# STM32L0x2 register map
File version: 1.7
CPU: CM0+ r0p0, little endian, MPU, no FPU, 2 interrupt priority bits
Registers are 32-bit, read-write, reset 0x0 unless marked. A register's access mark holds for its fields unless they carry their own. Offsets are from the block's base; [hi:lo] are bit positions; {n}, {i} and the like mark numbered series; 'fields as' and 'values as' point back to an identical list.

## SYSCFG — System configuration controller and Comparator
Base 0x40010000
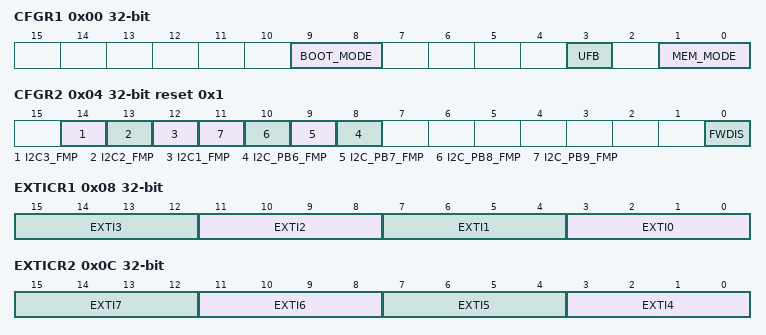
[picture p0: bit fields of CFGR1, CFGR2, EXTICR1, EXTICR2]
0x00 CFGR1 access not given — SYSCFG configuration register 1
  [9:8] BOOT_MODE ro — Boot mode selected by the boot pins status bits
    0=Main Flash memory boot mode; 1=System Flash memory boot mode; 3=SRAM (Embedded SRAM boot mode)
  [3] UFB — User bank swapping
    0=Bank1 (Flash Program memory Bank 1 is mapped at 0x0800 0000 (and aliased at 0x0000 0000 if MEM_MODE=00) and Data EEPROM Bank 1 at 0x0808 0000 (aliased at 0x0008 0000 if MEM_MODE=00)); 1=Bank2 (Flash Program memory Bank 2 is mapped at 0x0800 0000 (and aliased at 0x0000 0000 if MEM_MODE=00) and Data EEPROM Bank 2 at 0x0808 0000 (and aliased at 0x0008 0000 if MEM_MODE=00))
  [1:0] MEM_MODE rw — Memory mapping selection bits
    0=Main Flash memory mapped at 0x0000_0000; 1=System Flash memory mapped at 0x0000_0000; 3=SRAM (Embedded SRAM mapped at 0x0000_0000)
0x04 CFGR2 reset 0x1 — SYSCFG configuration register 2
  [14] I2C3_FMP — I2C3 Fm+ drive capability enable bit
    0=Standard (FM+ mode is controlled by I2C_Pxx_FMP bits only); 1=FMP (FM+ mode is enabled on all I2C3 pins selected through selection bits in GPIOx_AFR registers)
  [13] I2C2_FMP — I2C2 Fm+ drive capability enable bit
    0=Standard (FM+ mode is controlled by I2C_Pxx_FMP bits only); 1=FMP (FM+ mode is enabled on all I2C2 pins selected through selection bits in GPIOx_AFR registers)
  [12] I2C1_FMP — I2C1 Fm+ drive capability enable bit
    0=Standard (FM+ mode is controlled by I2C_Pxx_FMP bits only); 1=FMP (FM+ mode is enabled on all I2C1 pins selected through selection bits in GPIOx_AFR registers)
  [n+2] I2C_PB{n}_FMP (n=6..9) — Fm+ drive capability on PB{n} enable bit
    0=Standard (PB{n} pin operate in standard mode); 1=FMP (I2C FM+ mode enabled on PB{n} and the Speed control is bypassed)
  [0] FWDIS — Firewall disable bit
    0=Enabled (Firewall access enabled); 1=Disabled (Firewall access disabled)
0x08 EXTICR1 — external interrupt configuration register 1
  [all] fields
    0=PA (Select PAx as the source input for the EXTIx external interrupt); 1=PB (Select PBx as the source input for the EXTIx external interrupt); 2=PC (Select PCx as the source input for the EXTIx external interrupt); 3=PD (Select PDx as the source input for the EXTIx external interrupt); 4=PE (Select PEx as the source input for the EXTIx external interrupt); 5=PH (Select PHx as the source input for the EXTIx external interrupt)
  [4n+3:4n] EXTI{n} (n=0..3) — EXTI x configuration (x = 0 to 3)
0x0C EXTICR2 — external interrupt configuration register 2
  [all] fields
    0=PA (Select PAx as the source input for the EXTIx external interrupt); 1=PB (Select PBx as the source input for the EXTIx external interrupt); 2=PC (Select PCx as the source input for the EXTIx external interrupt); 3=PD (Select PDx as the source input for the EXTIx external interrupt); 4=PE (Select PEx as the source input for the EXTIx external interrupt)
  [4n-13:4n-16] EXTI{n} (n=4..7) — EXTI x configuration (x = 4 to 7)
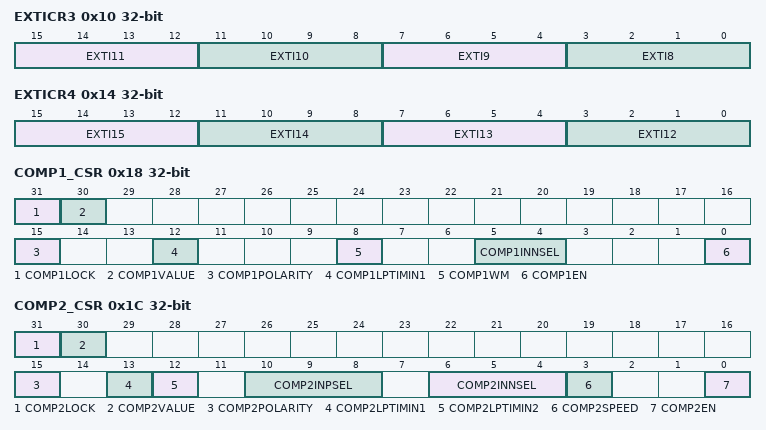
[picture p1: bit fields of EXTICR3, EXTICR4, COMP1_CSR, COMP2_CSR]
0x10 EXTICR3 — external interrupt configuration register 3
  [all] fields
    values as the fields of EXTICR1
  [15:12] EXTI11 — EXTI x configuration (x = 8 to 11)
  [11:8] EXTI10
  [7:4] EXTI9 — EXTI x configuration (x = 8 to 11)
  [3:0] EXTI8 — EXTI x configuration (x = 8 to 11)
0x14 EXTICR4 — external interrupt configuration register 4
  [all] fields
    values as the fields of EXTICR2
  [15:12] EXTI15 — EXTI x configuration (x = 12 to 15)
  [11:8] EXTI14
  [7:4] EXTI13
  [3:0] EXTI12
0x18 COMP1_CSR access per field — Comparator 1 control and status register
  [31] COMP1LOCK ro — COMP1_CSR register lock bit
    0=ReadWrite (COMP1_CSR[31:0] for comparator 1 are read/write); 1=ReadOnly (COMP1_CSR[31:0] for comparator 1 are read-only)
  [30] COMP1VALUE ro — Comparator 1 output status bit
    0=NotEqual (Comparator values are not equal); 1=Equal (Comparator values are equal)
  [15] COMP1POLARITY rw — Comparator 1 polarity selection bit
    0=NotInverted (Comparator 1 output value not inverted); 1=Inverted (Comparator 1 output value inverted)
  [12] COMP1LPTIMIN1 rw — Comparator 1 LPTIM input propagation bit
    0=Gated (Comparator 1 output gated); 1=NotGated (Comparator 1 output sent to LPTIM input 1)
  [8] COMP1WM rw — Comparator 1 window mode selection bit
    0=PA1 (Plus input of comparator 1 connected to PA1); 1=Comp2Plus (Plus input of comparator 1 shorted with Plus input of comparator 2 (see COMP1_CSR))
  [5:4] COMP1INNSEL rw — Comparator 1 Input Minus connection configuration bit
    0=VREFINT; 1=PA0; 2=PA4; 3=PA5
  [0] COMP1EN rw — Comparator 1 enable bit
    0=Disabled (Comparator 1 switched OFF); 1=Enabled (Comparator 1 switched ON)
0x1C COMP2_CSR access per field — Comparator 2 control and status register
  [31] COMP2LOCK ro — COMP2_CSR register lock bit
    0=ReadWrite (COMP2_CSR[31:0] for comparator 2 are read/write); 1=ReadOnly (COMP2_CSR[31:0] for comparator 2 are read-only)
  [30] COMP2VALUE ro — Comparator 2 output status bit
    values as COMP1_CSR.COMP1VALUE
  [15] COMP2POLARITY rw — Comparator 2 polarity selection bit
    0=NotInverted (Comparator 2 output value not inverted); 1=Inverted (Comparator 2 output value inverted)
  [13] COMP2LPTIMIN1 rw — Comparator 2 LPTIM input 1 propagation bit
    0=Gated (Comparator 2 output gated); 1=NotGated (Comparator 2 output sent to LPTIM input 1)
  [12] COMP2LPTIMIN2 rw — Comparator 2 LPTIM input 2 propagation bit
    0=Gated (Comparator 2 output gated); 1=NotGated (Comparator 2 output sent to LPTIM input 2)
  [10:8] COMP2INPSEL rw — Comparator 2 Input Plus connection configuration bit
    0=PA3; {v}=PB{v+3} (v=1..4); 5=PA7
  [6:4] COMP2INNSEL rw — Comparator 2 Input Minus connection configuration bit
    0=VREFINT; 1=PA2; 2=PA4; 3=PA5; 4=VREFINT_Div4 (1/4 VREFINT); 5=VREFINT_Div2 (1/2 VREFINT); 6=VREFINT_Div3_4 (3/4 VREFINT); 7=PB3
  [3] COMP2SPEED rw — Comparator 2 power mode selection bit
    0=Slow speed; 1=Fast speed
  [0] COMP2EN rw — Comparator 2 enable bit
    0=Disabled (Comparator 2 switched OFF); 1=Enabled (Comparator 2 switched ON)
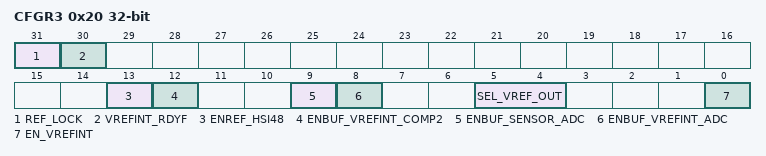
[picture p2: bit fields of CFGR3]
0x20 CFGR3 access not given — SYSCFG configuration register 3
  [31] REF_LOCK rw — SYSCFG_CFGR3 lock bit
    0=ReadWrite (SYSCFG_CFGR3[31:0] bits are read/write); 1=ReadOnly (SYSCFG_CFGR3[31:0] bits are read-only)
  [30] VREFINT_RDYF ro — VREFINT ready flag
    0=NotReady (VREFINT OFF); 1=Ready (VREFINT ready)
  [13] ENREF_HSI48 — VREFINT reference for HSI48 oscillator enable bit
  [12] ENBUF_VREFINT_COMP2 — VREFINT reference for COMP2 scaler enable bit
    0=Disabled (Disables the buffer used to generate VREFINT references for COMP2); 1=Enabled (Enables the buffer used to generate VREFINT references for COMP2)
  [9] ENBUF_SENSOR_ADC rw — Sensor reference for ADC enable bit
    0=Disabled (Disables the buffer used to generate VREFINT reference for the temperature sensor); 1=Enabled (Enables the buffer used to generate VREFINT reference for the temperature sensor)
  [8] ENBUF_VREFINT_ADC — VREFINT reference for ADC enable bit
    0=Disabled (Disables the buffer used to generate VREFINT reference for the ADC); 1=Enabled (Enables the buffer used to generate VREFINT reference for the ADC)
  [5:4] SEL_VREF_OUT rw — BGAP_ADC connection bit
    0=NoConnection (no pad connected); 1=PB0 (PB0 connected); 2=PB1 (PB1 connected); 3=Both (PB0 and PB1 connected)
  [0] EN_VREFINT — VREFINT enable and scaler control for COMP2 enable bit
    0=Disabled (VREFINT voltage disabled in low-power mode (if ULP=1) and scaler for COMP2 disabled); 1=Enabled (VREFINT voltage enabled in low-power mode and scaler for COMP2 enabled)
